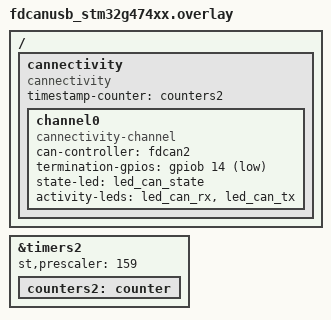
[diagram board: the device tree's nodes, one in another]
/*
 * Copyright (c) 2025 <knippenberg@filics.eu>
 *
 * SPDX-License-Identifier: Apache-2.0
 */

#include <zephyr/dt-bindings/gpio/gpio.h>
#include "../app.overlay"

/ {
	cannectivity: cannectivity {
		compatible = "cannectivity";
		timestamp-counter = <&counters2>;

		channel0 {
			compatible = "cannectivity-channel";
			can-controller = <&fdcan2>;
			termination-gpios = <&gpiob 14 GPIO_ACTIVE_LOW>;
			state-led = <&led_can_state>;
			activity-leds = <&led_can_rx &led_can_tx>;
		};
	};
};

&timers2 {
	st,prescaler = <159>;
	counters2: counter {
		status = "okay";
	};
};
